# f2838x_cm_cm_memcfg_regs register map
Vendor: Texas Instruments
Peripheral module from a debugger description file (folder C2000).
Address unit: 16 bits
Registers are 32-bit, read-write, no defined reset value unless marked. A register's access mark holds for its fields unless they carry their own. Offsets are as the file gives them; lines under a group give offsets from that group; [hi:lo] are bit positions; {n}, {i} and the like mark numbered series; 'fields as' and 'values as' point back to an identical list; <NAME> marks a mode.

## CM_MEMCFG_REGS — CM MEMCFG Registers
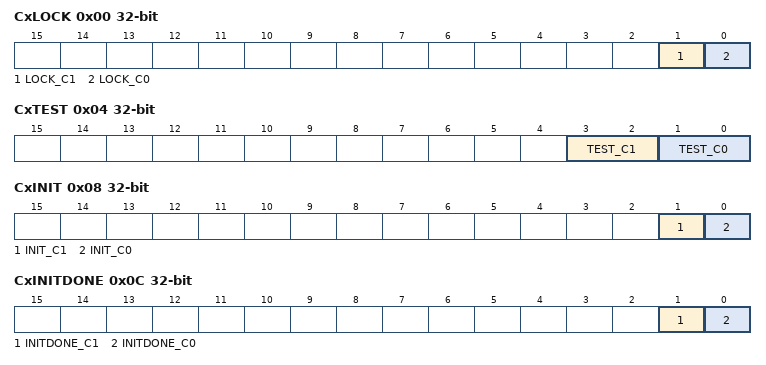
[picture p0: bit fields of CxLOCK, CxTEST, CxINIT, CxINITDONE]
0x00 CxLOCK — C RAM Config Lock Register
  [1] LOCK_C1 — C1 RAM Lock bits
  [0] LOCK_C0 — C0 RAM Lock bits
0x04 CxTEST — C RAM TEST Register
  [3:2] TEST_C1 — Selects the different modes for C1 RAM
  [1:0] TEST_C0 — Selects the different modes for C0 RAM
0x08 CxINIT — C RAM Init Register
  [1] INIT_C1 — RAM Initialization control for C1 RAM.
  [0] INIT_C0 — RAM Initialization control for C0 RAM.
0x0C CxINITDONE ro — C RAM Initialization Status Register
  [1] INITDONE_C1 — RAM Initialization status for C1 RAM.
  [0] INITDONE_C0 — RAM Initialization status for C0 RAM.
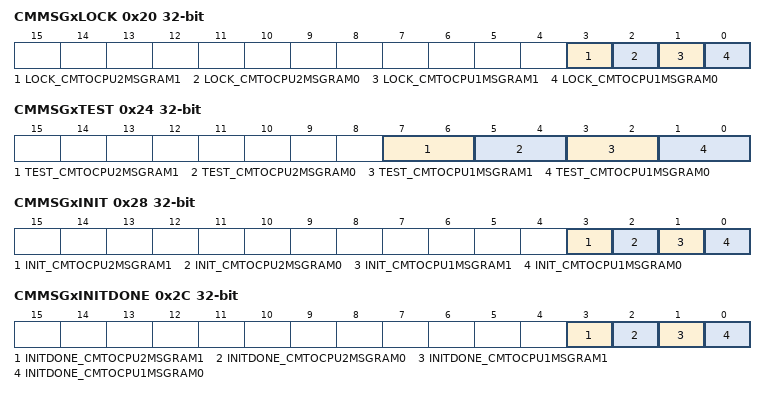
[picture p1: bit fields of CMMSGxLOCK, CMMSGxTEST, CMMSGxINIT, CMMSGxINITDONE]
0x20 CMMSGxLOCK — CM Messae RAM Config Lock Register
  [3] LOCK_CMTOCPU2MSGRAM1 — Message RAM CMTOCPU2MSGRAM1 Lock bits
  [2] LOCK_CMTOCPU2MSGRAM0 — Message RAM CMTOCPU2MSGRAM0 Lock bits
  [1] LOCK_CMTOCPU1MSGRAM1 — Message RAM CMTOCPU1MSGRAM1 Lock bits
  [0] LOCK_CMTOCPU1MSGRAM0 — Message RAM CMTOCPU1MSGRAM0 Lock bits
0x24 CMMSGxTEST — CM Messae RAM TEST Register
  [7:6] TEST_CMTOCPU2MSGRAM1 — Selects the different modes for Message RAM CMTOCPU2MSGRAM1
  [5:4] TEST_CMTOCPU2MSGRAM0 — Selects the different modes for Message RAM CMTOCPU2MSGRAM0
  [3:2] TEST_CMTOCPU1MSGRAM1 — Selects the different modes for Message RAM CMTOCPU1MSGRAM1
  [1:0] TEST_CMTOCPU1MSGRAM0 — Selects the different modes for Message RAM CMTOCPU1MSGRAM0
0x28 CMMSGxINIT — CM Messae RAM Init Register
  [3] INIT_CMTOCPU2MSGRAM1 — RAM Initialization control for Message RAM CMTOCPU2MSGRAM1
  [2] INIT_CMTOCPU2MSGRAM0 — RAM Initialization control for Message RAM CMTOCPU2MSGRAM0
  [1] INIT_CMTOCPU1MSGRAM1 — RAM Initialization control for Message RAM CMTOCPU1MSGRAM1
  [0] INIT_CMTOCPU1MSGRAM0 — RAM Initialization control for Message RAM CMTOCPU1MSGRAM0
0x2C CMMSGxINITDONE ro — CM Messae RAM Initialization Status Register
  [3] INITDONE_CMTOCPU2MSGRAM1 — RAM Initialization status for Message RAM CMTOCPU2MSGRAM1
  [2] INITDONE_CMTOCPU2MSGRAM0 — RAM Initialization status for Message RAM CMTOCPU2MSGRAM0
  [1] INITDONE_CMTOCPU1MSGRAM1 — RAM Initialization status for Message RAM CMTOCPU1MSGRAM1
  [0] INITDONE_CMTOCPU1MSGRAM0 — RAM Initialization status for Message RAM CMTOCPU1MSGRAM0
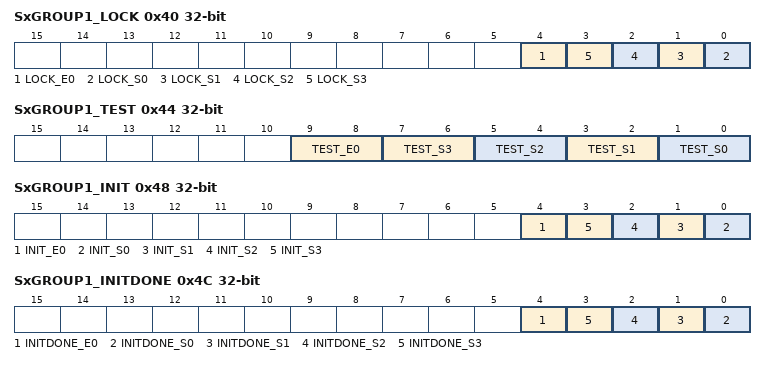
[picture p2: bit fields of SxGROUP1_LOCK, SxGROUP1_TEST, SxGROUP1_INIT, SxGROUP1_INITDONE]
0x40 SxGROUP1_LOCK — Group1 S and E RAM Config Lock Register
  [4] LOCK_E0 — E0 RAM Lock bits
  [n] LOCK_S{n} (n=0..3) — S{n} RAM Lock bits
0x44 SxGROUP1_TEST — Group1 S and E RAM TEST Register
  [9:8] TEST_E0 — Selects the different modes for E0 RAM
  [2n+1:2n] TEST_S{n} (n=0..3) — Selects the different modes for S{n} RAM
0x48 SxGROUP1_INIT — Group1 S and E RAM Init Register
  [4] INIT_E0 — RAM Initialization control for E0 RAM.
  [n] INIT_S{n} (n=0..3) — RAM Initialization control for S{n} RAM.
0x4C SxGROUP1_INITDONE ro — Group1 S and E RAM Initialization Status Register
  [4] INITDONE_E0 — RAM Initialization status for E0 RAM.
  [n] INITDONE_S{n} (n=0..3) — RAM Initialization status for S{n} RAM.
0x80 ROM_LOCK — ROM Config Lock Register
  [0] LOCK_BOOTROM — BOOTROM Lock bits
0x84 ROM_TEST
  [1:0] TEST_BOOTROM — Selects the different modes for BOOTROM
0x88 ROM_FORCE_ERROR
  [0] FORCE_BOOTROM_ERROR — Force Bootrom Parity Error
0xA0 PERI_MEM_TEST_LOCK — Peripheral Memory Test Lock Register
  [0] LOCK_PERI_MEM_TEST_CONTROL — PERI_MEM_TEST_CONTROL Lock bit
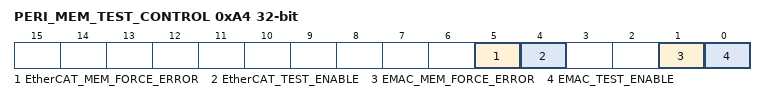
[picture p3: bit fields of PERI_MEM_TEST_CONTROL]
0xA4 PERI_MEM_TEST_CONTROL — Peripheral Memory Test control Register
  [5] EtherCAT_MEM_FORCE_ERROR — Force Parity Error on EtherCAT RAM
  [4] EtherCAT_TEST_ENABLE — EtherCAT Test mode enable
  [1] EMAC_MEM_FORCE_ERROR — Force Parity Error on EMAC RAM
  [0] EMAC_TEST_ENABLE — EMAC Test mode enable
